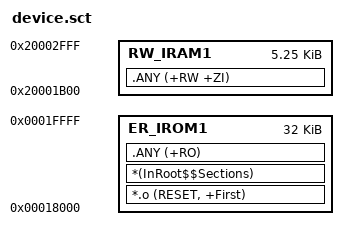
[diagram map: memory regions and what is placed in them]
; The platform allocates 32k flash and 5376 bytes RAM

LR_IROM1 0x00018000 0x00008000  {    ; load region size_region
  ER_IROM1 0x00018000 0x00008000  {  ; load address = execution address
   *.o (RESET, +First)
   *(InRoot$$Sections)
   .ANY (+RO)
  }
  RW_IRAM1 0x20001b00 0x00001500  {  ; RW data
   .ANY (+RW +ZI)
  }
}

